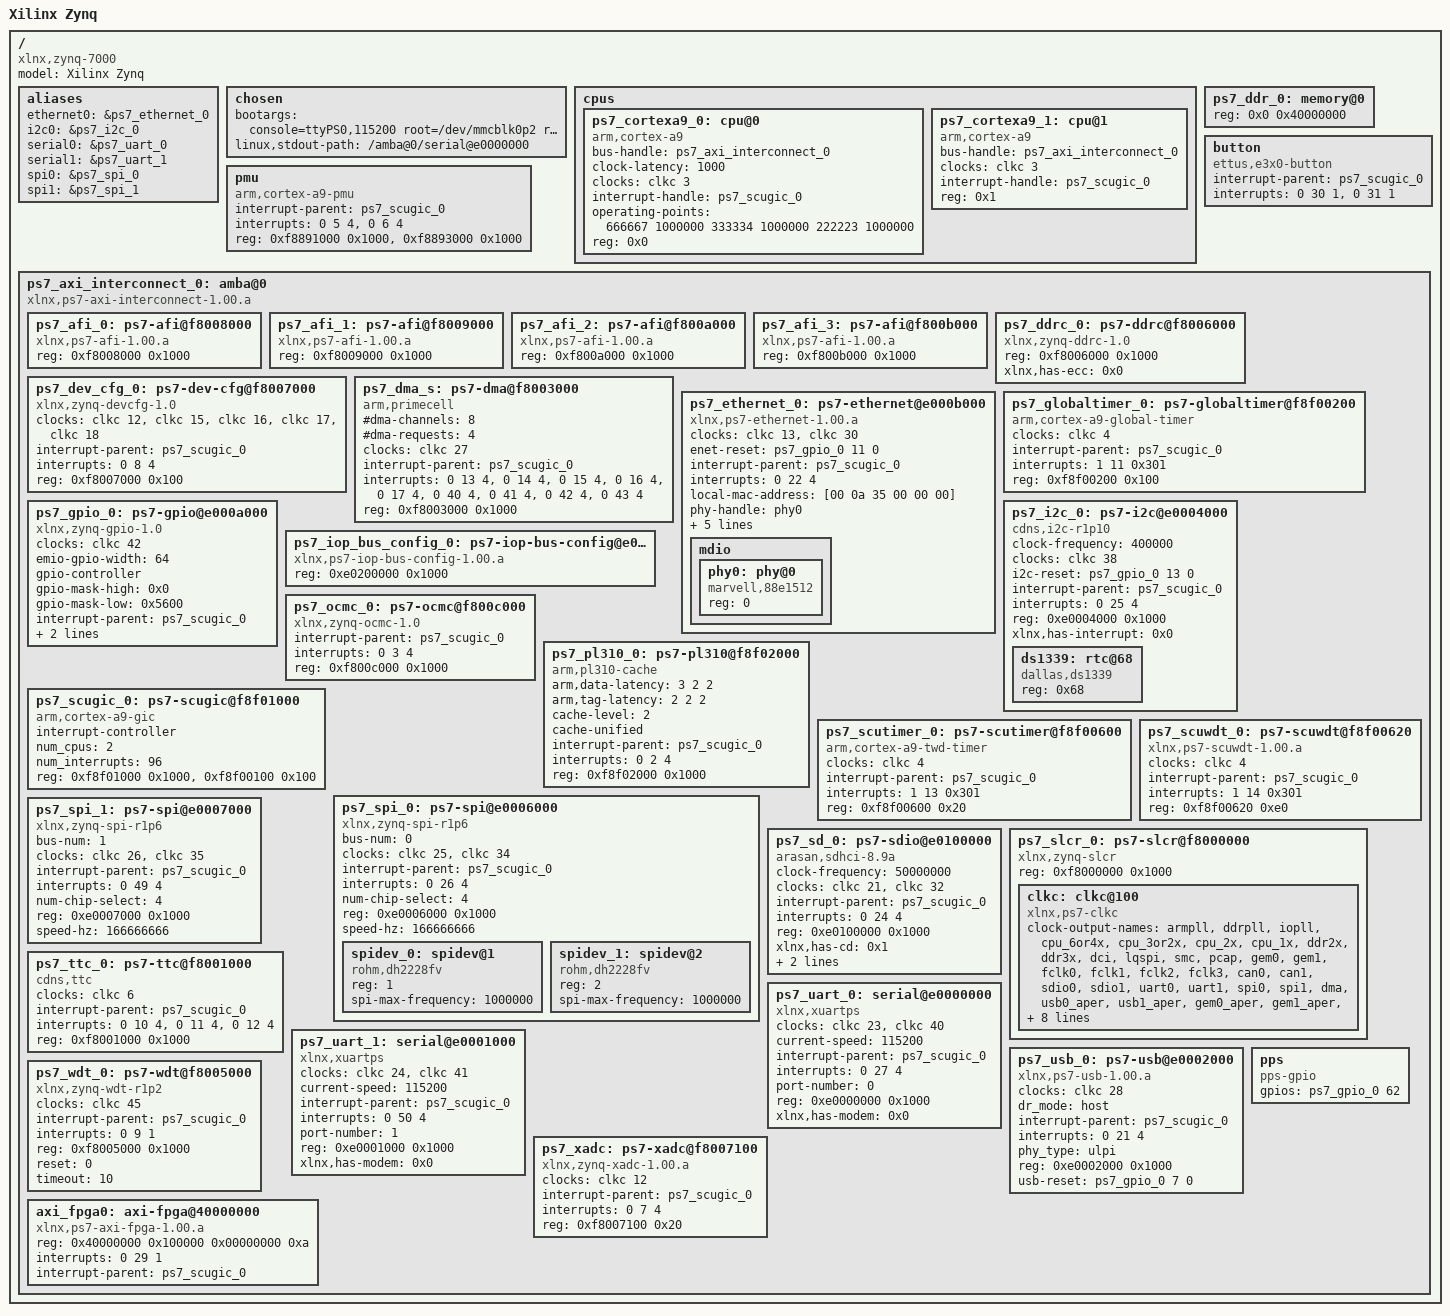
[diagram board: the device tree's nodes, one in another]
/*
 * Device Tree Generator version: 1.1
 *
 * (C) Copyright 2007-2013 Xilinx, Inc.
 * (C) Copyright 2007-2013 Michal Simek
 * (C) Copyright 2007-2012 PetaLogix Qld Pty Ltd
 *
 * Michal SIMEK <monstr@monstr.eu>
 *
 * CAUTION: This file is automatically generated by libgen.
 * Version: Xilinx EDK 14.5 EDK_P.58f
 *
 */

/dts-v1/;
/ {
	#address-cells = <1>;
	#size-cells = <1>;
	compatible = "xlnx,zynq-7000";
	model = "Xilinx Zynq";
	aliases {
		ethernet0 = &ps7_ethernet_0;
		i2c0 = &ps7_i2c_0;
		serial0 = &ps7_uart_0;
		serial1 = &ps7_uart_1;
		spi0 = &ps7_spi_0;
		spi1 = &ps7_spi_1;
	} ;
	chosen {
		bootargs = "console=ttyPS0,115200 root=/dev/mmcblk0p2 rootwait ro earlyprintk";
		linux,stdout-path = "/amba@0/serial@e0000000";
	} ;
	cpus {
		#address-cells = <1>;
		#size-cells = <0>;
		ps7_cortexa9_0: cpu@0 {
			bus-handle = <&ps7_axi_interconnect_0>;
			clock-latency = <1000>;
			clocks = <&clkc 3>;
			compatible = "arm,cortex-a9";
			device_type = "cpu";
			interrupt-handle = <&ps7_scugic_0>;
			operating-points = <666667 1000000 333334 1000000 222223 1000000>;
			reg = <0x0>;
		} ;
		ps7_cortexa9_1: cpu@1 {
			bus-handle = <&ps7_axi_interconnect_0>;
			clocks = <&clkc 3>;
			compatible = "arm,cortex-a9";
			device_type = "cpu";
			interrupt-handle = <&ps7_scugic_0>;
			reg = <0x1>;
		} ;
	} ;
	pmu {
		compatible = "arm,cortex-a9-pmu";
		interrupt-parent = <&ps7_scugic_0>;
		interrupts = <0 5 4>, <0 6 4>;
		reg = <0xf8891000 0x1000>, <0xf8893000 0x1000>;
		reg-names = "cpu0", "cpu1";
	} ;
	ps7_ddr_0: memory@0 {
		device_type = "memory";
		reg = <0x0 0x40000000>;
	} ;
	button {
		compatible = "ettus,e3x0-button";
		interrupt-parent = <&ps7_scugic_0>;
		interrupts = <0 30 1>, <0 31 1>;
		interrupt-names = "press", "release";
	} ;
	ps7_axi_interconnect_0: amba@0 {
		#address-cells = <1>;
		#size-cells = <1>;
		compatible = "xlnx,ps7-axi-interconnect-1.00.a", "simple-bus";
		ranges ;
		ps7_afi_0: ps7-afi@f8008000 {
			compatible = "xlnx,ps7-afi-1.00.a";
			reg = <0xf8008000 0x1000>;
		} ;
		ps7_afi_1: ps7-afi@f8009000 {
			compatible = "xlnx,ps7-afi-1.00.a";
			reg = <0xf8009000 0x1000>;
		} ;
		ps7_afi_2: ps7-afi@f800a000 {
			compatible = "xlnx,ps7-afi-1.00.a";
			reg = <0xf800a000 0x1000>;
		} ;
		ps7_afi_3: ps7-afi@f800b000 {
			compatible = "xlnx,ps7-afi-1.00.a";
			reg = <0xf800b000 0x1000>;
		} ;
		ps7_ddrc_0: ps7-ddrc@f8006000 {
			compatible = "xlnx,zynq-ddrc-1.0";
			reg = <0xf8006000 0x1000>;
			xlnx,has-ecc = <0x0>;
		} ;
		ps7_dev_cfg_0: ps7-dev-cfg@f8007000 {
			clock-names = "ref_clk", "fclk0", "fclk1", "fclk2", "fclk3";
			clocks = <&clkc 12>, <&clkc 15>, <&clkc 16>, <&clkc 17>, <&clkc 18>;
			compatible = "xlnx,zynq-devcfg-1.0";
			interrupt-parent = <&ps7_scugic_0>;
			interrupts = <0 8 4>;
			reg = <0xf8007000 0x100>;
		} ;
		ps7_dma_s: ps7-dma@f8003000 {
			#dma-cells = <1>;
			#dma-channels = <8>;
			#dma-requests = <4>;
			clock-names = "apb_pclk";
			clocks = <&clkc 27>;
			compatible = "arm,primecell", "arm,pl330";
			interrupt-names = "abort", "dma0", "dma1", "dma2", "dma3",
				"dma4", "dma5", "dma6", "dma7";
			interrupt-parent = <&ps7_scugic_0>;
			interrupts = <0 13 4>, <0 14 4>, <0 15 4>, <0 16 4>, <0 17 4>, <0 40 4>, <0 41 4>, <0 42 4>, <0 43 4>;
			reg = <0xf8003000 0x1000>;
		} ;
		ps7_ethernet_0: ps7-ethernet@e000b000 {
			#address-cells = <1>;
			#size-cells = <0>;
			clock-names = "ref_clk", "aper_clk";
			clocks = <&clkc 13>, <&clkc 30>;
			compatible = "xlnx,ps7-ethernet-1.00.a";
			enet-reset = <&ps7_gpio_0 11 0>;
			interrupt-parent = <&ps7_scugic_0>;
			interrupts = <0 22 4>;
			local-mac-address = [00 0a 35 00 00 00];
			phy-handle = <&phy0>;
			phy-mode = "rgmii-id";
			reg = <0xe000b000 0x1000>;
			xlnx,eth-mode = <0x1>;
			xlnx,has-mdio = <0x1>;
			xlnx,ptp-enet-clock = <111111115>;
			mdio {
				#address-cells = <1>;
				#size-cells = <0>;
				phy0: phy@0 {
					compatible = "marvell,88e1512";
					device_type = "ethernet-phy";
					reg = <0>;
				} ;
			} ;
		} ;
		ps7_globaltimer_0: ps7-globaltimer@f8f00200 {
			clocks = <&clkc 4>;
			compatible = "arm,cortex-a9-global-timer";
			interrupt-parent = <&ps7_scugic_0>;
			interrupts = <1 11 0x301>;
			reg = <0xf8f00200 0x100>;
		} ;
		ps7_gpio_0: ps7-gpio@e000a000 {
			#gpio-cells = <2>;
			clocks = <&clkc 42>;
			compatible = "xlnx,zynq-gpio-1.0";
			emio-gpio-width = <64>;
			gpio-controller ;
			gpio-mask-high = <0x0>;
			gpio-mask-low = <0x5600>;
			interrupt-parent = <&ps7_scugic_0>;
			interrupts = <0 20 4>;
			reg = <0xe000a000 0x1000>;
		} ;
		ps7_i2c_0: ps7-i2c@e0004000 {
			clock-frequency = <400000>;
			clocks = <&clkc 38>;
			compatible = "cdns,i2c-r1p10";
			i2c-reset = <&ps7_gpio_0 13 0>;
			interrupt-parent = <&ps7_scugic_0>;
			interrupts = <0 25 4>;
			reg = <0xe0004000 0x1000>;
			xlnx,has-interrupt = <0x0>;
			#address-cells = <1>;
			#size-cells = <0>;

			ds1339: rtc@68 {
				compatible = "dallas,ds1339";
				reg = <0x68>;
			};

		} ;
		ps7_iop_bus_config_0: ps7-iop-bus-config@e0200000 {
			compatible = "xlnx,ps7-iop-bus-config-1.00.a";
			reg = <0xe0200000 0x1000>;
		} ;
		ps7_ocmc_0: ps7-ocmc@f800c000 {
			compatible = "xlnx,zynq-ocmc-1.0";
			interrupt-parent = <&ps7_scugic_0>;
			interrupts = <0 3 4>;
			reg = <0xf800c000 0x1000>;
		} ;
		ps7_pl310_0: ps7-pl310@f8f02000 {
			arm,data-latency = <3 2 2>;
			arm,tag-latency = <2 2 2>;
			cache-level = <2>;
			cache-unified ;
			compatible = "arm,pl310-cache";
			interrupt-parent = <&ps7_scugic_0>;
			interrupts = <0 2 4>;
			reg = <0xf8f02000 0x1000>;
		} ;
		ps7_scugic_0: ps7-scugic@f8f01000 {
			#address-cells = <2>;
			#interrupt-cells = <3>;
			#size-cells = <1>;
			compatible = "arm,cortex-a9-gic", "arm,gic";
			interrupt-controller ;
			num_cpus = <2>;
			num_interrupts = <96>;
			reg = <0xf8f01000 0x1000>, <0xf8f00100 0x100>;
		} ;
		ps7_scutimer_0: ps7-scutimer@f8f00600 {
			clocks = <&clkc 4>;
			compatible = "arm,cortex-a9-twd-timer";
			interrupt-parent = <&ps7_scugic_0>;
			interrupts = <1 13 0x301>;
			reg = <0xf8f00600 0x20>;
		} ;
		ps7_scuwdt_0: ps7-scuwdt@f8f00620 {
			clocks = <&clkc 4>;
			compatible = "xlnx,ps7-scuwdt-1.00.a";
			device_type = "watchdog";
			interrupt-parent = <&ps7_scugic_0>;
			interrupts = <1 14 0x301>;
			reg = <0xf8f00620 0xe0>;
		} ;
		ps7_spi_0: ps7-spi@e0006000 {
			bus-num = <0>;
			clock-names = "ref_clk", "pclk";
			clocks = <&clkc 25>, <&clkc 34>;
			compatible = "xlnx,zynq-spi-r1p6";
			interrupt-parent = <&ps7_scugic_0>;
			interrupts = <0 26 4>;
			num-chip-select = <4>;
			reg = <0xe0006000 0x1000>;
			speed-hz = <166666666>;
			#address-cells = <1>;
			#size-cells = <0>;
			spidev_0: spidev@1 {
				compatible = "rohm,dh2228fv";
				reg = <1>;
				spi-max-frequency = <1000000>;
			} ;
			spidev_1: spidev@2 {
				compatible = "rohm,dh2228fv";
				reg = <2>;
				spi-max-frequency = <1000000>;
			} ;

		} ;
		ps7_spi_1: ps7-spi@e0007000 {
			bus-num = <1>;
			clock-names = "ref_clk", "pclk";
			clocks = <&clkc 26>, <&clkc 35>;
			compatible = "xlnx,zynq-spi-r1p6";
			interrupt-parent = <&ps7_scugic_0>;
			interrupts = <0 49 4>;
			num-chip-select = <4>;
			reg = <0xe0007000 0x1000>;
			speed-hz = <166666666>;
			#address-cells = <1>;
			#size-cells = <0>;
		} ;
		ps7_sd_0: ps7-sdio@e0100000 {
			clock-frequency = <50000000>;
			clock-names = "clk_xin", "clk_ahb";
			clocks = <&clkc 21>, <&clkc 32>;
			compatible = "arasan,sdhci-8.9a";
			interrupt-parent = <&ps7_scugic_0>;
			interrupts = <0 24 4>;
			reg = <0xe0100000 0x1000>;
			xlnx,has-cd = <0x1>;
			xlnx,has-power = <0x0>;
			xlnx,has-wp = <0x0>;
		} ;
		ps7_slcr_0: ps7-slcr@f8000000 {
			#address-cells = <1>;
			#size-cells = <1>;
			compatible = "xlnx,zynq-slcr", "syscon";
			ranges ;
			reg = <0xf8000000 0x1000>;
			clkc: clkc@100 {
				#clock-cells = <1>;
				clock-output-names = "armpll", "ddrpll", "iopll", "cpu_6or4x", "cpu_3or2x",
					"cpu_2x", "cpu_1x", "ddr2x", "ddr3x", "dci",
					"lqspi", "smc", "pcap", "gem0", "gem1",
					"fclk0", "fclk1", "fclk2", "fclk3", "can0",
					"can1", "sdio0", "sdio1", "uart0", "uart1",
					"spi0", "spi1", "dma", "usb0_aper", "usb1_aper",
					"gem0_aper", "gem1_aper", "sdio0_aper", "sdio1_aper", "spi0_aper",
					"spi1_aper", "can0_aper", "can1_aper", "i2c0_aper", "i2c1_aper",
					"uart0_aper", "uart1_aper", "gpio_aper", "lqspi_aper", "smc_aper",
					"swdt", "dbg_trc", "dbg_apb";
				compatible = "xlnx,ps7-clkc";
				fclk-enable = <0xf>;
				ps-clk-frequency = <33333333>;
				reg = <0x100 0x100>;
			} ;
		} ;
		ps7_ttc_0: ps7-ttc@f8001000 {
			clocks = <&clkc 6>;
			compatible = "cdns,ttc";
			interrupt-names = "ttc0", "ttc1", "ttc2";
			interrupt-parent = <&ps7_scugic_0>;
			interrupts = <0 10 4>, <0 11 4>, <0 12 4>;
			reg = <0xf8001000 0x1000>;
		} ;
		ps7_uart_0: serial@e0000000 {
			clock-names = "ref_clk", "aper_clk";
			clocks = <&clkc 23>, <&clkc 40>;
			compatible = "xlnx,xuartps";
			current-speed = <115200>;
			device_type = "serial";
			interrupt-parent = <&ps7_scugic_0>;
			interrupts = <0 27 4>;
			port-number = <0>;
			reg = <0xe0000000 0x1000>;
			xlnx,has-modem = <0x0>;
		} ;
		ps7_uart_1: serial@e0001000 {
			clock-names = "ref_clk", "aper_clk";
			clocks = <&clkc 24>, <&clkc 41>;
			compatible = "xlnx,xuartps";
			current-speed = <115200>;
			device_type = "serial";
			interrupt-parent = <&ps7_scugic_0>;
			interrupts = <0 50 4>;
			port-number = <1>;
			reg = <0xe0001000 0x1000>;
			xlnx,has-modem = <0x0>;
		} ;
		ps7_usb_0: ps7-usb@e0002000 {
			clocks = <&clkc 28>;
			compatible = "xlnx,ps7-usb-1.00.a", "xlnx,zynq-usb-1.00.a";
			dr_mode = "host";
			interrupt-parent = <&ps7_scugic_0>;
			interrupts = <0 21 4>;
			phy_type = "ulpi";
			reg = <0xe0002000 0x1000>;
			usb-reset = <&ps7_gpio_0 7 0>;
		} ;
		ps7_wdt_0: ps7-wdt@f8005000 {
			clocks = <&clkc 45>;
			compatible = "xlnx,zynq-wdt-r1p2";
			device_type = "watchdog";
			interrupt-parent = <&ps7_scugic_0>;
			interrupts = <0 9 1>;
			reg = <0xf8005000 0x1000>;
			reset = <0>;
			timeout = <10>;
		} ;
		ps7_xadc: ps7-xadc@f8007100 {
			clocks = <&clkc 12>;
			compatible = "xlnx,zynq-xadc-1.00.a";
			interrupt-parent = <&ps7_scugic_0>;
			interrupts = <0 7 4>;
			reg = <0xf8007100 0x20>;
		} ;
		axi_fpga0: axi-fpga@40000000 {
			compatible = "xlnx,ps7-axi-fpga-1.00.a";
			reg = <0x40000000 0x100000
				0x00000000 0xa>;
			interrupts = <0 29 1>;
			interrupt-parent = <&ps7_scugic_0>;
		};
		pps {
			compatible = "pps-gpio";
			gpios = <&ps7_gpio_0 62 0>;
		};
	} ;
} ;
